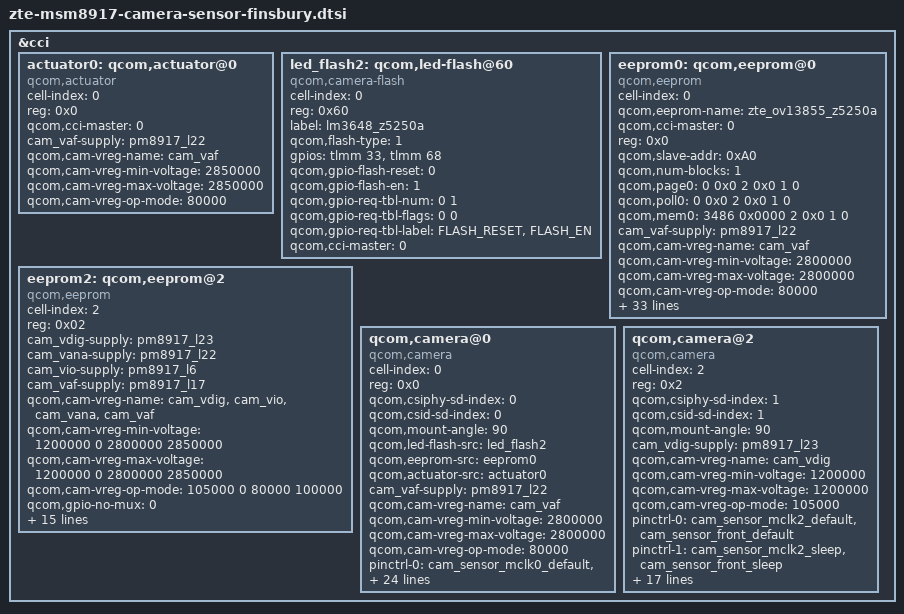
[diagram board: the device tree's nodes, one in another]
/*
 * Copyright (c) 2016, The Linux Foundation. All rights reserved.
 *
 * This program is free software; you can redistribute it and/or modify
 * it under the terms of the GNU General Public License version 2 and
 * only version 2 as published by the Free Software Foundation.
 *
 * This program is distributed in the hope that it will be useful,
 * but WITHOUT ANY WARRANTY; without even the implied warranty of
 * MERCHANTABILITY or FITNESS FOR A PARTICULAR PURPOSE.  See the
 * GNU General Public License for more details.
 */
&cci {
	actuator0: qcom,actuator@0 {
		cell-index = <0>;
		reg = <0x0>;
		compatible = "qcom,actuator";
		qcom,cci-master = <0>;
		cam_vaf-supply = <&pm8917_l22>;
		qcom,cam-vreg-name = "cam_vaf";
		qcom,cam-vreg-min-voltage = <2850000>;
		qcom,cam-vreg-max-voltage = <2850000>;
		qcom,cam-vreg-op-mode = <80000>;
	};

	led_flash2: qcom,led-flash@60{
		cell-index = <0>;
		compatible = "qcom,camera-flash";
		reg = <0x60>;
		label = "lm3648_z5250a";
		qcom,flash-type = <1>;
		gpios = <&tlmm 33 0>,
			<&tlmm 68 0>;
		qcom,gpio-flash-reset = <0>;
		qcom,gpio-flash-en = <1>;
		qcom,gpio-req-tbl-num = <0 1>;
		qcom,gpio-req-tbl-flags = <0 0>;
		qcom,gpio-req-tbl-label = "FLASH_RESET", "FLASH_EN";
		qcom,cci-master = <0>;
	};

	eeprom0: qcom,eeprom@0 {
		cell-index = <0>;
		compatible = "qcom,eeprom";
		qcom,eeprom-name = "zte_ov13855_z5250a";
		qcom,cci-master = <0>;
		reg = <0x0>;
		qcom,slave-addr = <0xA0>;
		qcom,num-blocks = <1>;
		qcom,page0 = <0 0x0 2 0x0 1 0>;
		qcom,poll0 = <0 0x0 2 0x0 1 0>;
		qcom,mem0 = <3486 0x0000 2 0x0 1 0>;
		cam_vaf-supply = <&pm8917_l22>;
		qcom,cam-vreg-name = "cam_vaf";
		qcom,cam-vreg-min-voltage = <2800000>;
		qcom,cam-vreg-max-voltage = <2800000>;
		qcom,cam-vreg-op-mode = <80000>;
		pinctrl-names = "cam_default", "cam_suspend";
		pinctrl-0 = <&cam_sensor_mclk0_default &cam_sensor_rear_default
					&cam_sensor_rear_vdig>;
		pinctrl-1 = <&cam_sensor_mclk0_sleep &cam_sensor_rear_sleep
					&cam_sensor_rear_vdig_sleep>;
		gpios = <&tlmm 26 0>,
				<&tlmm 36 0>,
				<&tlmm 35 0>,
				<&tlmm 129 0>,
				<&tlmm 62 0>,
				<&tlmm 68 0>;
		qcom,gpio-reset = <1>;
		qcom,gpio-standby = <2>;
		qcom,gpio-vana = <3>;
		qcom,gpio-vdig = <4>;
		qcom,gpio-vio = <5>;
		qcom,gpio-req-tbl-num = <0 1 2 3 4 5>;
		qcom,gpio-req-tbl-flags = <1 0 0 0 0 0>;
		qcom,gpio-req-tbl-label = "CAMIF_MCLK0",
				"CAM_RESET0",
				"CAM_STANDBY0",
				"CAM_VANA",
				"CAM_VDIG",
				"CAM_VIO";
		qcom,cam-power-seq-type = "sensor_gpio","sensor_gpio","sensor_gpio",
			"sensor_gpio","sensor_gpio", "sensor_vreg","sensor_gpio","sensor_gpio","sensor_clk";
		qcom,cam-power-seq-val = "sensor_gpio_reset","sensor_gpio_standby","sensor_gpio_vio",
			"sensor_gpio_vana","sensor_gpio_vdig",
			"cam_vaf","sensor_gpio_reset","sensor_gpio_standby","sensor_cam_mclk";
		qcom,cam-power-seq-cfg-val = <0 0 1 1 1 0 1 1 24000000>;
		qcom,cam-power-seq-delay = <5 5 5 5 5 5 5 5 5>;
		status = "ok";
		clocks = <&clock_gcc clk_mclk0_clk_src>,
				<&clock_gcc clk_gcc_camss_mclk0_clk>;
		clock-names = "cam_src_clk", "cam_clk";
		qcom,clock-rates = <24000000 0>;
	};

	eeprom2: qcom,eeprom@2 {
		cell-index = <2>;
		compatible = "qcom,eeprom";
		reg = <0x02>;
		cam_vdig-supply = <&pm8917_l23>;
		cam_vana-supply = <&pm8917_l22>;
		cam_vio-supply = <&pm8917_l6>;
		cam_vaf-supply = <&pm8917_l17>;
		qcom,cam-vreg-name = "cam_vdig", "cam_vio", "cam_vana",
								"cam_vaf";
		qcom,cam-vreg-min-voltage = <1200000 0 2800000 2850000>;
		qcom,cam-vreg-max-voltage = <1200000 0 2800000 2850000>;
		qcom,cam-vreg-op-mode = <105000 0 80000 100000>;
		qcom,gpio-no-mux = <0>;
		pinctrl-names = "cam_default", "cam_suspend";
		pinctrl-0 = <&cam_sensor_mclk2_default
					&cam_sensor_front1_default>;
		pinctrl-1 = <&cam_sensor_mclk2_sleep
					&cam_sensor_front1_sleep>;
		gpios = <&tlmm 28 0>,
			<&tlmm 40 0>,
			<&tlmm 39 0>;
		qcom,gpio-reset = <1>;
		qcom,gpio-standby = <2>;
		qcom,gpio-req-tbl-num = <0 1 2>;
		qcom,gpio-req-tbl-flags = <1 0 0>;
		qcom,gpio-req-tbl-label = "CAMIF_MCLK2",
					  "CAM_RESET2",
					  "CAM_STANDBY2";
		qcom,cci-master = <0>;
		status = "ok";
		clocks = <&clock_gcc clk_mclk2_clk_src>,
			<&clock_gcc clk_gcc_camss_mclk2_clk>;
		clock-names = "cam_src_clk", "cam_clk";
		qcom,clock-rates = <19200000 0>;
	};

	qcom,camera@0 {
		cell-index = <0>;
		compatible = "qcom,camera";
		reg = <0x0>;
		qcom,csiphy-sd-index = <0>;
		qcom,csid-sd-index = <0>;
		qcom,mount-angle = <90>;
		qcom,led-flash-src = <&led_flash2>;
		qcom,eeprom-src = <&eeprom0>;
		qcom,actuator-src = <&actuator0>;
		//cam_vio-supply = <&pm8917_l6>;
		cam_vaf-supply = <&pm8917_l22>;
		qcom,cam-vreg-name = "cam_vaf";
		qcom,cam-vreg-min-voltage = <2800000>;
		qcom,cam-vreg-max-voltage = <2800000>;
		qcom,cam-vreg-op-mode = <80000>;
		pinctrl-names = "cam_default", "cam_suspend";
		pinctrl-0 = <&cam_sensor_mclk0_default
				&cam_sensor_rear_default
				&cam_sensor_rear_vdig>;
		pinctrl-1 = <&cam_sensor_mclk0_sleep &cam_sensor_rear_sleep
				&cam_sensor_rear_vdig_sleep>;
		gpios = <&tlmm 26 0>,
			<&tlmm 36 0>,
			<&tlmm 35 0>,
			<&tlmm 129 0>,
			<&tlmm 62 0>,
			<&tlmm 68 0>,
			<&tlmm 33 0>;
		qcom,gpio-reset = <1>;
		qcom,gpio-standby = <2>;
		qcom,gpio-vana = <3>;
		qcom,gpio-vdig = <4>;
		qcom,gpio-vio = <5>;
		qcom,gpio-vaf = <6>;
		qcom,gpio-req-tbl-num = <0 1 2 3 4 5 6>;
		qcom,gpio-req-tbl-flags = <1 0 0 0 0 0 0>;
		qcom,gpio-req-tbl-label = "CAMIF_MCLK0",
			"CAM_RESET0",
			"CAM_STANDBY0",
			"CAM_VANA",
			"CAM_VDIG",
			"CAM_VIO",
			"CAM_VAF";
		qcom,sensor-position = <0>;
		qcom,sensor-mode = <0>;
		qcom,cci-master = <0>;
		status = "ok";
		clocks = <&clock_gcc clk_mclk0_clk_src>,
				<&clock_gcc clk_gcc_camss_mclk0_clk>;
		clock-names = "cam_src_clk", "cam_clk";
		qcom,clock-rates = <24000000 0>;
	};

	qcom,camera@2 {
		cell-index = <2>;
		compatible = "qcom,camera";
		reg = <0x2>;
		qcom,csiphy-sd-index = <1>;
		qcom,csid-sd-index = <1>;
		qcom,mount-angle = <90>;
		//cam_vdig-supply = <&pm8917_l6>;
		//qcom,actuator-src = <&actuator2>;
		//qcom,eeprom-src = <&eeprom2>;
		cam_vdig-supply = <&pm8917_l23>;
		//cam_vana-supply = <&pm8917_l22>;
		//cam_vio-supply = <&pm8917_l6>;
		qcom,cam-vreg-name = "cam_vdig";
		qcom,cam-vreg-min-voltage = <1200000>;
		qcom,cam-vreg-max-voltage = <1200000>;
		qcom,cam-vreg-op-mode = <105000>;
		pinctrl-names = "cam_default", "cam_suspend";
		pinctrl-0 = <&cam_sensor_mclk2_default
				&cam_sensor_front_default>;
		pinctrl-1 = <&cam_sensor_mclk2_sleep
				&cam_sensor_front_sleep>;
		gpios = <&tlmm 28 0>,
			<&tlmm 40 0>,
			<&tlmm 39 0>,
			<&tlmm 96 0>,
			<&tlmm 68 0>;
		qcom,gpio-reset = <1>;
		qcom,gpio-standby = <2>;
		qcom,gpio-vana = <3>;
		qcom,gpio-vio = <4>;
		qcom,gpio-req-tbl-num = <0 1 2 3 4>;
		qcom,gpio-req-tbl-flags = <1 0 0 0 0>;
		qcom,gpio-req-tbl-label = "CAMIF_MCLK1",
			"CAM_RESET1",
			"CAM_STANDBY1",
			"CAM_VANA1",
			"CAM_VIO1";
		qcom,sensor-position = <1>;
		qcom,sensor-mode = <0>;
		qcom,cci-master = <0>;
		clocks = <&clock_gcc clk_mclk2_clk_src>,
				<&clock_gcc clk_gcc_camss_mclk2_clk>;
		clock-names = "cam_src_clk", "cam_clk";
		qcom,clock-rates = <24000000 0>;
	};
};
